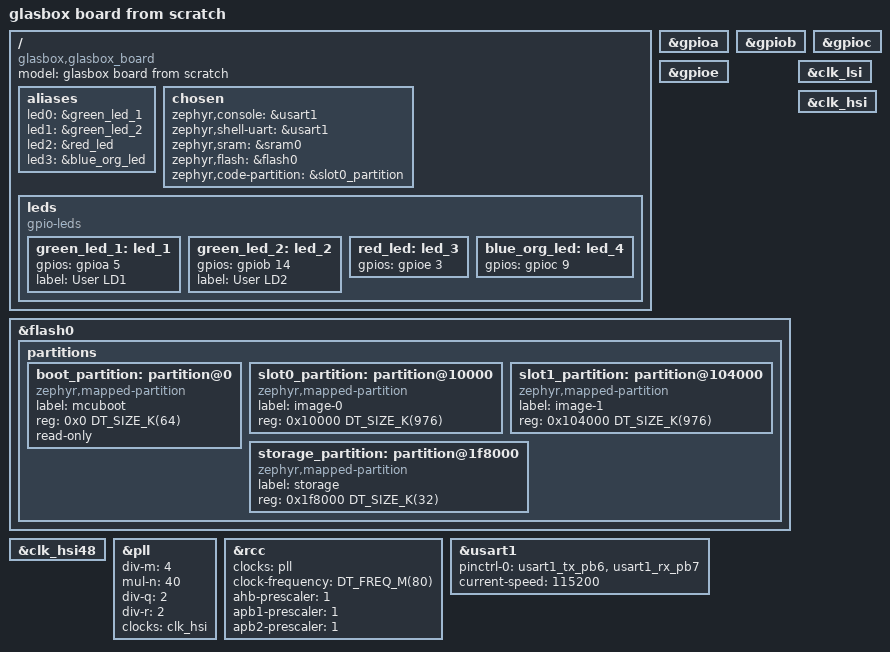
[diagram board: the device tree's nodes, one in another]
/dts-v1/;
#include <st/l4/stm32l4s5Xi.dtsi>
#include <st/l4/stm32l4s5vitx-pinctrl.dtsi>
/ {
	model = "glasbox board from scratch";
	compatible = "glasbox,glasbox_board";

    aliases {
        led0 = &green_led_1;
        led1 = &green_led_2;
        led2 = &red_led;
        led3 = &blue_org_led;
    };

    chosen {
		zephyr,console = &usart1;
		zephyr,shell-uart = &usart1;
        zephyr,sram = &sram0;
		zephyr,flash = &flash0;
		zephyr,code-partition = &slot0_partition;
    };

    leds {
        compatible = "gpio-leds";
        green_led_1: led_1 {
			gpios = <&gpioa 5 GPIO_ACTIVE_HIGH>;
			label = "User LD1";
		};

		green_led_2: led_2 {
			gpios = <&gpiob 14 GPIO_ACTIVE_HIGH>;
			label = "User LD2";
		};
         red_led: led_3 {
            gpios = <&gpioe 3 GPIO_ACTIVE_HIGH>;
        };

        blue_org_led: led_4 {
            gpios = <&gpioc 9 GPIO_ACTIVE_HIGH>;
        };
    };

 }; 

 &gpioa {
    status="okay";
 };

  &gpiob {
    status="okay";
 };

  &gpioc {
    status="okay";
 };

  &gpioe {
    status="okay";
 };

 &flash0 {
	partitions {
		#address-cells = <1>;
		#size-cells = <1>;
		ranges;

		boot_partition: partition@0 {
			compatible = "zephyr,mapped-partition";
			label = "mcuboot";
			reg = <0x0 DT_SIZE_K(64)>;
			read-only;
		};

		slot0_partition: partition@10000 {
			compatible = "zephyr,mapped-partition";
			label = "image-0";
			reg = <0x10000 DT_SIZE_K(976)>;
		};

		slot1_partition: partition@104000 {
			compatible = "zephyr,mapped-partition";
			label = "image-1";
			reg = <0x104000 DT_SIZE_K(976)>;
		};

		storage_partition: partition@1f8000 {
			compatible = "zephyr,mapped-partition";
			label = "storage";
			reg = <0x1f8000 DT_SIZE_K(32)>;
		};
	};
};

&clk_lsi {
	status = "okay";
};

&clk_hsi48 {
	status = "okay";
};

&clk_hsi {
	status = "okay";
};

&pll {
	div-m = <4>;
	mul-n = <40>;
	div-q = <2>;
	div-r = <2>;
	clocks = <&clk_hsi>;
	status = "okay";
};

&rcc {
	clocks = <&pll>;
	clock-frequency = <DT_FREQ_M(80)>;
	ahb-prescaler = <1>;
	apb1-prescaler = <1>;
	apb2-prescaler = <1>;
};

&usart1 {
	pinctrl-0 = <&usart1_tx_pb6 &usart1_rx_pb7>;
	pinctrl-names = "default";
	current-speed = <115200>;
	status = "okay";
};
